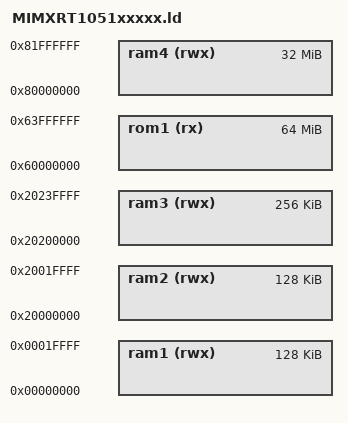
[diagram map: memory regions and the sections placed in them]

MEMORY
{
  rom1 (rx) : ORIGIN = 0x60000000, LENGTH = 0x4000000
  ram1 (rwx) : ORIGIN = 0x00000000, LENGTH = 0x020000
  ram2 (rwx) : ORIGIN = 0x20000000, LENGTH = 0x020000
  ram3 (rwx) : ORIGIN = 0x20200000, LENGTH = 0x040000
  ram4 (rwx) : ORIGIN = 0x80000000, LENGTH = 0x02000000
}

